# bao1x register map
Vendor: baochip; File version: 1.0
Baochip-1x SoC
Registers are 32-bit, read-write, reset 0x0 unless marked. A register's access mark holds for its fields unless they carry their own. Offsets are from the block's base; lines under a group give offsets from that group; [hi:lo] are bit positions; {n}, {i} and the like mark numbered series; 'fields as' and 'values as' point back to an identical list; <NAME> marks a mode.

## Memory map
0x40000000 RRC size 0xF4
0x40010000 QFC size 0x54
0x40011000 PL230 blocks up to offset 0x50 — PL230 DMA Controller Core
0x40012000 MDMA size 0x60
0x40013000 MBOX_APB size 0x20
0x40014000 CORESUB_SRAMTRM size 0x34
0x40028000 SCE_GLBSFR size 0xF0
0x40029000 SCEDMA size 0x78
0x4002B000 COMBOHASH size 0x64
0x4002C000 PKE size 0x68
0x4002D000 AES size 0x40
0x4002E000 TRNG size 0x50
0x4002F000 ALU size 0x40
0x40040000 SYSCTRL size 0xB0
0x40041000 WDG_INTF size 0x4
0x40042000 DUART size 0x10
0x40043000 TIMER_INTF size 0x4
0x40044000 EVC size 0xA4
0x40045000 RBIST_WRP size 0xC
0x40052000 MESH size 0x40
0x40053000 SENSORC size 0x50
0x40054000 GLUECHAIN size 0x10
0x40060000 AO_SYSCTRL size 0x68
0x40064000 DKPC size 0x34
0x40065000 AOBUREG size 0x20
0x50100000 UDMA_CTRL size 0xC
0x50101000 UDMA_UART_0 size 0x38
0x50102000 UDMA_UART_1 size 0x38
0x50103000 UDMA_UART_2 size 0x38
0x50104000 UDMA_UART_3 size 0x38
0x50105000 UDMA_SPIM_0 size 0x34
0x50106000 UDMA_SPIM_1 size 0x34
0x50107000 UDMA_SPIM_2 size 0x34
0x50108000 UDMA_SPIM_3 size 0x34
0x50109000 UDMA_I2C_0 size 0x3C
0x5010A000 UDMA_I2C_1 size 0x3C
0x5010B000 UDMA_I2C_2 size 0x3C
0x5010C000 UDMA_I2C_3 size 0x3C
0x5010D000 UDMA_SDIO size 0x4C
0x5010E000 UDMA_I2S size 0x30
0x5010F000 UDMA_CAMERA size 0x38
0x50110000 UDMA_FILTER size 0x64
0x50111000 UDMA_SCIF size 0x3C
0x50112000 UDMA_SPIS_0 size 0x38
0x50113000 UDMA_SPIS_1 size 0x38
0x50114000 UDMA_ADC size 0x14
0x50120000 PWM size 0x150
0x50121000 SDDC size 0x1F4
0x50122000 APB_THRU size 0x4
0x50124000 BIO_BDMA size 0x100
0x50129000 BIO_FIFO0 size 0x44
0x5012A000 BIO_FIFO1 size 0x44
0x5012B000 BIO_FIFO2 size 0x44
0x5012C000 BIO_FIFO3 size 0x44
0x5012F000 IOX size 0x278
0xE0000000 D11CTIME size 0x8
0xE0001000 SUSRES size 0x2C
0xE0002000 COREUSER size 0x18
0xE0003000 CSRTEST size 0x8
0xE0004000 IRQARRAY0 size 0x18
0xE0005000 IRQARRAY1 size 0x18
{0xDFFFC000+0x1000*n} IRQARRAY{n} size 0x18 (n=10..19)
{0xE000E000+0x1000*n} IRQARRAY{n} size 0x18 (n=2..9)
0xE0018000 MAILBOX size 0x24
0xE0019000 MB_CLIENT size 0x20
0xE001A000 RESETVALUE size 0x4
0xE001B000 TICKTIMER size 0x24
0xE001C000 TIMER0 size 0x20

## Interrupts
{n} irqarray{n} (IRQARRAY{n}) (n=0..19)
20 ticktimer (TICKTIMER)
21 susres (SUSRES)
22 mailbox (MAILBOX)
23 mb_client (MB_CLIENT)
30 timer0 (TIMER0)

## PL230 — PL230 DMA Controller Core
Base 0x40011000
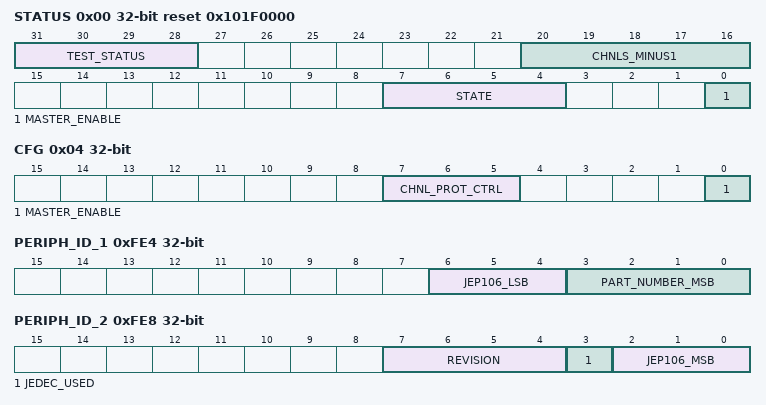
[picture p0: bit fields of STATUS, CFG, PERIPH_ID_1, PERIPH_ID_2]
0x00 STATUS ro reset 0x101F0000 (reset mask 0xFFFFFF0F) — DMA Status Register
  [31:28] TEST_STATUS — Test status configuration
  [20:16] CHNLS_MINUS1 — Number of available DMA channels minus 1
  [7:4] STATE — Current state of the control machine
  [0] MASTER_ENABLE — Master enable status
0x04 CFG wo reset not defined — DMA Configuration Register
  [7:5] CHNL_PROT_CTRL — Set AHB-Lite configuration
  [0] MASTER_ENABLE
0x08 CTRLBASEPTR — DMA Control Data Base Pointer Register
  [31:8] CTRL_BASE_PTR
0x0C ALTCTRLBASEPTR ro — DMA Channel Alternate Control Data Base Pointer Register
  [31:0] ALT_CTRL_BASE_PTR
0x10 DMA_WAITONREQ_STATUS ro — Channel wait on request status
  [7:0] DMA_WAITONREQ_STATUS — Wait on request status, one bit per channel
0x14 CHNLSWREQUEST wo reset not defined — DMA Channel Software Request Register
  [7:0] CHNL_SW_REQUEST
0x18 CHNLUSEBURSTSET — DMA Channel Useburst Set Register
  [7:0] CHNL_USEBURST_SET
0x1C CHNLUSEBURSTCLR wo reset not defined — DMA Channel Useburst Clear Register
  [7:0] CHNL_USEBURST_CLR
0x20 CHNLREQMASKSET — DMA Channel Request Mask Set Register
  [7:0] CHNL_REQ_MASK_SET
0x24 CHNLREQMASKCLR wo reset not defined — DMA Channel Request Mask Clear Register
  [7:0] CHNL_REQ_MASK_CLR
0x28 CHNLENABLESET — DMA Channel Enable Set Register
  [7:0] CHNL_ENABLE_SET
0x2C CHNLENABLECLR wo reset not defined — DMA Channel Enable Clear Register
  [7:0] CHNL_ENABLE_CLR
0x30 CHNLPRIALTSET — DMA Channel Primary-Alternate Set Register
  [7:0] CHNL_PRI_ALT_SET
0x34 CHNLPRIALTCLR wo reset not defined — DMA Channel Primary-Alternate Clear Register
  [7:0] CHNL_PRI_ALT_CLR
0x38 CHNLPRIORITYSET — DMA Channel Priority Set Register
  [7:0] CHNL_PRIORITY_SET
0x3C CHNLPRIORITYCLR wo reset not defined — DMA Channel Priority Clear Register
  [7:0] CHNL_PRIORITY_CLR
0x4C ERRCLR — DMA Bus Error Clear Register
  [0] ERR_CLR
0xFE0 PERIPH_ID_0 — Peripheral ID byte 0
  [7:0] PART_NUMBER_LSB ro — Identifies the part number
0xFE4 PERIPH_ID_1 — Peripheral ID byte 1
  [6:4] JEP106_LSB ro — Designer ID LSB
  [3:0] PART_NUMBER_MSB ro — Identifies the part number
0xFE8 PERIPH_ID_2 — Peripheral ID byte 2
  [7:4] REVISION ro — Identifies revision number of peripheral
  [3] JEDEC_USED ro — Identifies if JP106 ID code is used
  [2:0] JEP106_MSB ro — Designer ID MSB
